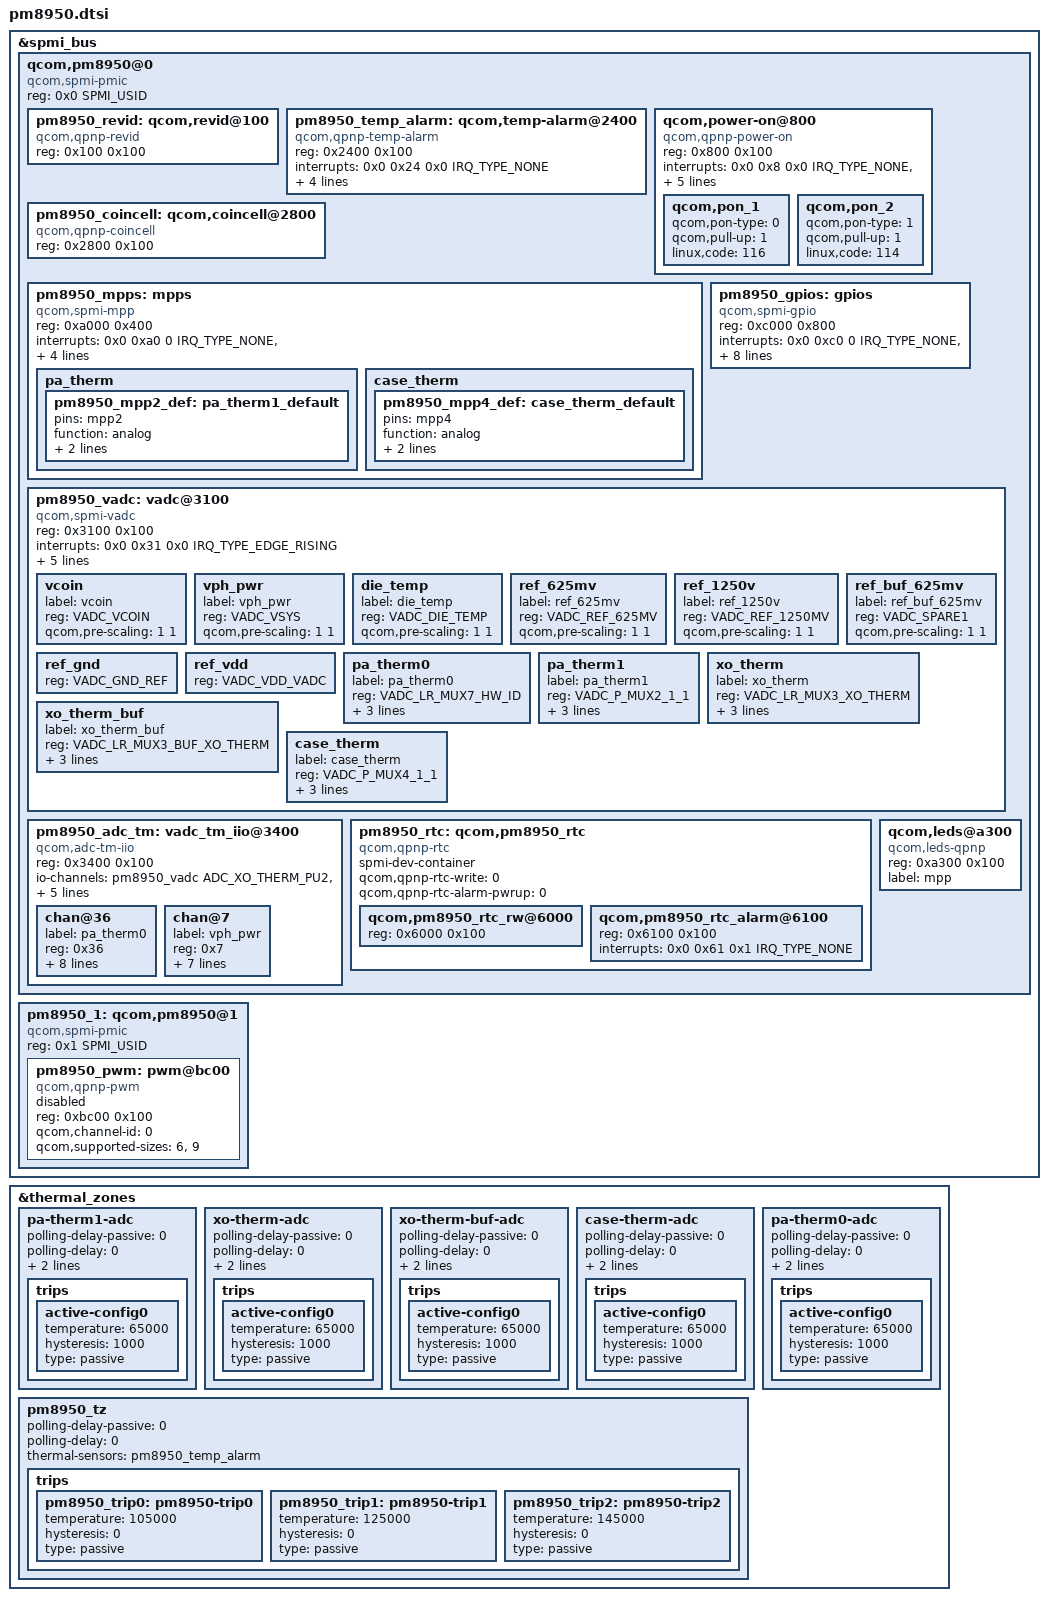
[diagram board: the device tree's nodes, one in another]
/* Copyright (c) 2015-2017, The Linux Foundation. All rights reserved.
 *
 * This program is free software; you can redistribute it and/or modify
 * it under the terms of the GNU General Public License version 2 and
 * only version 2 as published by the Free Software Foundation.
 *
 * This program is distributed in the hope that it will be useful,
 * but WITHOUT ANY WARRANTY; without even the implied warranty of
 * MERCHANTABILITY or FITNESS FOR A PARTICULAR PURPOSE.  See the
 * GNU General Public License for more details.
 */
#include <dt-bindings/pinctrl/qcom,pmic-mpp.h>
#include <dt-bindings/pinctrl/qcom,pmic-gpio.h>
#include <dt-bindings/iio/qcom,spmi-vadc.h>

&spmi_bus {
	qcom,pm8950@0 {
		compatible ="qcom,spmi-pmic";
		reg = <0x0 SPMI_USID>;
		#address-cells = <2>;
		#size-cells = <0>;

		pm8950_revid: qcom,revid@100 {
			compatible = "qcom,qpnp-revid";
			reg = <0x100 0x100>;
		};

		pm8950_temp_alarm: qcom,temp-alarm@2400 {
			compatible = "qcom,qpnp-temp-alarm";
			reg = <0x2400 0x100>;
			interrupts = <0x0 0x24 0x0 IRQ_TYPE_NONE>;
			label = "pm8950_tz";
			qcom,channel-num = <8>;
			qcom,threshold-set = <0>;
			qcom,temp_alarm-vadc = <&pm8950_vadc>;
			#thermal-sensor-cells = <0>;
		};

		qcom,power-on@800 {
			compatible = "qcom,qpnp-power-on";
			reg = <0x800 0x100>;
			interrupts = <0x0 0x8 0x0 IRQ_TYPE_NONE>,
				<0x0 0x8 0x1 IRQ_TYPE_NONE>,
				<0x0 0x8 0x4 IRQ_TYPE_NONE>,
				<0x0 0x8 0x5 IRQ_TYPE_NONE>;
			interrupt-names = "kpdpwr", "resin",
				"resin-bark", "kpdpwr-resin-bark";
			qcom,pon-dbc-delay = <15625>;
			qcom,system-reset;

			qcom,pon_1 {
				qcom,pon-type = <0>;
				qcom,pull-up = <1>;
				linux,code = <116>;
			};

			qcom,pon_2 {
				qcom,pon-type = <1>;
				qcom,pull-up = <1>;
				linux,code = <114>;
			};
		};

		pm8950_coincell: qcom,coincell@2800 {
			compatible = "qcom,qpnp-coincell";
			reg = <0x2800 0x100>;
		};

		pm8950_mpps: mpps {
			compatible = "qcom,spmi-mpp";
			reg = <0xa000 0x400>;

			interrupts = <0x0 0xa0 0 IRQ_TYPE_NONE>,
				<0x0 0xa1 0 IRQ_TYPE_NONE>,
				<0x0 0xa2 0 IRQ_TYPE_NONE>,
				<0x0 0xa3 0 IRQ_TYPE_NONE>;
			interrupt-names = "pm8950_mpp1", "pm8950_mpp2",
					"pm8950_mpp3", "pm8950_mpp4";

			gpio-controller;
			#gpio-cells = <2>;

			/* MPP_2: PA_THERM1 */
			pa_therm {
				pm8950_mpp2_def: pa_therm1_default {
					pins = "mpp2";
					function = "analog";
					input-enable;
					qcom,amux-route = <PMIC_MPP_AMUX_ROUTE_CH6>;
					/* Function constant, Enable MPP */
				};
			};

			/* MPP_4: QUIET_THERM */
			case_therm {
				pm8950_mpp4_def: case_therm_default {
					pins = "mpp4";
					function = "analog";
					input-enable;
					qcom,amux-route = <PMIC_MPP_AMUX_ROUTE_CH8>;
					/* Function constant, Enable MPP */
				};
			};
		};

		pm8950_gpios: gpios {
			compatible = "qcom,spmi-gpio";
			reg = <0xc000 0x800>;

			interrupts =    <0x0 0xc0 0 IRQ_TYPE_NONE>,
					<0x0 0xc1 0 IRQ_TYPE_NONE>,
					<0x0 0xc3 0 IRQ_TYPE_NONE>,
					<0x0 0xc4 0 IRQ_TYPE_NONE>,
					<0x0 0xc5 0 IRQ_TYPE_NONE>,
					<0x0 0xc6 0 IRQ_TYPE_NONE>,
					<0x0 0xc7 0 IRQ_TYPE_NONE>;
			interrupt-names = "pm8950_gpio1", "pm8950_gpio2",
					  "pm8950_gpio4", "pm8950_gpio5",
					  "pm8950_gpio6", "pm8950_gpio7",
					  "pm8950_gpio8";

			gpio-controller;
			#gpio-cells = <2>;
			qcom,gpios-disallowed = <3>;
		};

		pm8950_vadc: vadc@3100 {
			compatible = "qcom,spmi-vadc";
			reg = <0x3100 0x100>;
			#address-cells = <1>;
			#size-cells = <0>;
			interrupts = <0x0 0x31 0x0 IRQ_TYPE_EDGE_RISING>;
			interrupt-names = "eoc-int-en-set";
			qcom,adc-bit-resolution = <15>;
			qcom,adc-vdd-reference = <1800>;
			qcom,vadc-poll-eoc;
			//qcom,pmic-revid = <&pm8950_revid>;
			#thermal-sensor-cells = <1>;
			#io-channel-cells = <1>;
			io-channel-ranges;
			pinctrl-names = "default";
			pinctrl-0 = <&pm8950_mpp2_def &pm8950_mpp4_def>;

			vcoin {
				label = "vcoin";
				reg = <VADC_VCOIN>;
				qcom,pre-scaling = <1 1>;
			};

			vph_pwr {
				label = "vph_pwr";
				reg = <VADC_VSYS>;
				qcom,pre-scaling = <1 1>;
			};

			die_temp {
				label = "die_temp";
				reg = <VADC_DIE_TEMP>;
				qcom,pre-scaling = <1 1>;
			};

			ref_625mv {
				label = "ref_625mv";
				reg = <VADC_REF_625MV>;
				qcom,pre-scaling = <1 1>;
			};

			ref_1250v {
				label = "ref_1250v";
				reg = <VADC_REF_1250MV>;
				qcom,pre-scaling = <1 1>;
			};

			ref_buf_625mv {
				label = "ref_buf_625mv";
				reg = <VADC_SPARE1>;
				qcom,pre-scaling = <1 1>;
			};

			ref_gnd {
				reg = <VADC_GND_REF>;
			};
			ref_vdd {
				reg = <VADC_VDD_VADC>;
			};

			pa_therm0 {
				label = "pa_therm0";
				reg = <VADC_LR_MUX7_HW_ID>;
				qcom,pre-scaling = <1 1>;
				qcom,ratiometric;
				qcom,hw-settle-time = <200>;

/*	To be fixed in qcom-spmi-vadc.c to select the right scale function
				qcom,scale-function = <2>;
*/
			};

			pa_therm1 {
				label = "pa_therm1";
				reg = <VADC_P_MUX2_1_1>;
				qcom,pre-scaling = <1 1>;
				qcom,ratiometric;
				qcom,hw-settle-time = <200>;

/*	To be fixed in qcom-spmi-vadc.c to select the right scale function
				qcom,scale-function = <2>;
				qcom,vadc-thermal-node;
*/
			};

			xo_therm {
				label = "xo_therm";
				reg = <VADC_LR_MUX3_XO_THERM>;
				qcom,pre-scaling = <1 1>;
				qcom,ratiometric;
				qcom,hw-settle-time = <200>;
/*	To be fixed in qcom-spmi-vadc.c to select the right scale function
				qcom,scale-function = <4>;
				qcom,vadc-thermal-node;
*/
			};

			xo_therm_buf {
				label = "xo_therm_buf";
				reg = <VADC_LR_MUX3_BUF_XO_THERM>;
				qcom,pre-scaling = <1 1>;
				qcom,ratiometric;
				qcom,hw-settle-time = <200>;
/*	To be fixed in qcom-spmi-vadc.c to select the right scale function
				qcom,scale-function = <4>;
				qcom,vadc-thermal-node;
*/
			};

			case_therm {
				label = "case_therm";
				reg = <VADC_P_MUX4_1_1>;
				qcom,pre-scaling = <1 1>;
				qcom,ratiometric;
				qcom,hw-settle-time = <200>;
/*	To be fixed in qcom-spmi-vadc.c to select the right scale function
				qcom,scale-function = <2>;
				qcom,vadc-thermal-node;
*/
			};
		};

		pm8950_adc_tm: vadc_tm_iio@3400 {
			//compatible = "qcom,qpnp-adc-tm";
			compatible = "qcom,adc-tm-iio"; /* tm is NOT IMPLEMENTED!!! */
			reg = <0x3400 0x100>;
			#address-cells = <1>;
			#size-cells = <0>;

			io-channels = <&pm8950_vadc ADC_XO_THERM_PU2>,
					<&pm8950_vadc VADC_P_MUX2_1_1>,
					<&pm8950_vadc VADC_VSYS>;

/*
			interrupts =	<0x0 0x34 0x0 IRQ_TYPE_NONE>,
					<0x0 0x34 0x3 IRQ_TYPE_NONE>,
					<0x0 0x34 0x4 IRQ_TYPE_NONE>;
			interrupt-names =	"eoc-int-en-set",
						"high-thr-en-set",
						"low-thr-en-set";
*/
			qcom,adc-bit-resolution = <15>;
			qcom,adc-vdd-reference = <1800>;
			qcom,adc_tm-vadc = <&pm8950_vadc>;
			//qcom,pmic-revid = <&pm8950_revid>;
			#thermal-sensor-cells = <1>;

			chan@36 {
				label = "pa_therm0";
				reg = <0x36>;
				qcom,decimation = <0>;
				qcom,pre-div-channel-scaling = <0>;
				qcom,calibration-type = "ratiometric";
				qcom,scale-function = <2>;
				qcom,hw-settle-time = <2>;
				qcom,fast-avg-setup = <0>;
				qcom,btm-channel-number = <0x48>;
				qcom,thermal-node;
			};

			chan@7 {
				label = "vph_pwr";
				reg = <0x7>;
				qcom,decimation = <0>;
				qcom,pre-div-channel-scaling = <1>;
				qcom,calibration-type = "absolute";
				qcom,scale-function = <0>;
				qcom,hw-settle-time = <0>;
				qcom,fast-avg-setup = <0>;
				qcom,btm-channel-number = <0x68>;
			};
		};

		pm8950_rtc: qcom,pm8950_rtc {
			spmi-dev-container;
			compatible = "qcom,qpnp-rtc";
			#address-cells = <1>;
			#size-cells = <1>;
			qcom,qpnp-rtc-write = <0>;
			qcom,qpnp-rtc-alarm-pwrup = <0>;

			qcom,pm8950_rtc_rw@6000 {
				reg = <0x6000 0x100>;
			};

			qcom,pm8950_rtc_alarm@6100 {
				reg = <0x6100 0x100>;
				interrupts = <0x0 0x61 0x1 IRQ_TYPE_NONE>;
			};
		};

		qcom,leds@a300 {
			compatible = "qcom,leds-qpnp";
			reg = <0xa300 0x100>;
			label = "mpp";
		};
	};

	pm8950_1: qcom,pm8950@1 {
		compatible ="qcom,spmi-pmic";
		reg = <0x1 SPMI_USID>;
		#address-cells = <2>;
		#size-cells = <0>;

		pm8950_pwm: pwm@bc00 {
			status = "disabled";
			compatible = "qcom,qpnp-pwm";
			reg = <0xbc00 0x100>;
			reg-names = "qpnp-lpg-channel-base";
			qcom,channel-id = <0>;
			qcom,supported-sizes = <6>, <9>;
			#pwm-cells = <2>;
		};
	};
};

&thermal_zones {
	pa-therm1-adc {
		polling-delay-passive = <0>;
		polling-delay = <0>;
		thermal-sensors = <&pm8950_vadc 0x11>;
		thermal-governor = "user_space";

		trips {
			active-config0 {
				temperature = <65000>;
				hysteresis = <1000>;
				type = "passive";
			};
		};
	};

	xo-therm-adc {
		polling-delay-passive = <0>;
		polling-delay = <0>;
		thermal-sensors = <&pm8950_vadc 0x32>;
		thermal-governor = "user_space";

		trips {
			active-config0 {
				temperature = <65000>;
				hysteresis = <1000>;
				type = "passive";
			};
		};
	};

	xo-therm-buf-adc {
		polling-delay-passive = <0>;
		polling-delay = <0>;
		thermal-sensors = <&pm8950_vadc 0x3c>;
		thermal-governor = "user_space";

		trips {
			active-config0 {
				temperature = <65000>;
				hysteresis = <1000>;
				type = "passive";
			};
		};
	};

	case-therm-adc {
		polling-delay-passive = <0>;
		polling-delay = <0>;
		thermal-sensors = <&pm8950_vadc 0x13>;
		thermal-governor = "user_space";

		trips {
			active-config0 {
				temperature = <65000>;
				hysteresis = <1000>;
				type = "passive";
			};
		};
	};

	pa-therm0-adc {
		polling-delay-passive = <0>;
		polling-delay = <0>;
		thermal-sensors = <&pm8950_adc_tm 0x36>;
		thermal-governor = "user_space";

		trips {
			active-config0 {
				temperature = <65000>;
				hysteresis = <1000>;
				type = "passive";
			};
		};
	};

	pm8950_tz {
		polling-delay-passive = <0>;
		polling-delay = <0>;
		thermal-sensors = <&pm8950_temp_alarm>;

		trips {
			pm8950_trip0: pm8950-trip0 {
				temperature = <105000>;
				hysteresis = <0>;
				type = "passive";
			};
			pm8950_trip1: pm8950-trip1 {
				temperature = <125000>;
				hysteresis = <0>;
				type = "passive";
			};
			pm8950_trip2: pm8950-trip2 {
				temperature = <145000>;
				hysteresis = <0>;
				type = "passive";
			};
		};
	};
};
